# PIC32MZ1025W104132 device description
Architecture: MIPS; Family: PIC32MZW; Series: PIC32MZW
Registers are 32-bit, read-write, no defined reset value unless marked. A register's access mark holds for its fields unless they carry their own. Offsets are from the block's base; [hi:lo] are bit positions; {n}, {i} and the like mark numbered series; 'fields as' and 'values as' point back to an identical list.

## CVD
Instances: CVD 0x1f824000 in periph_pb2
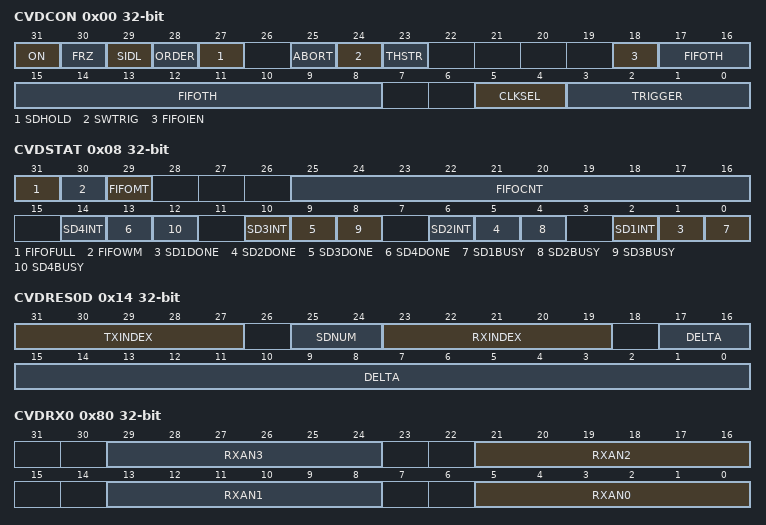
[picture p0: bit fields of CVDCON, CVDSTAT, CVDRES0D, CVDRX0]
0x00 CVDCON
  [31] ON, [30] FRZ, [29] SIDL, [28] ORDER, [27] SDHOLD, [25] ABORT, [24] SWTRIG, [23] THSTR, [18] FIFOIEN, [17:8] FIFOTH, [5:4] CLKSEL, [3:0] TRIGGER
0x04 CVDADC
  [23:0] ADCCON
0x08 CVDSTAT
  [31] FIFOFULL, [30] FIFOWM, [29] FIFOMT, [25:16] FIFOCNT, [4n-2] SD{n}INT (n=1..4), [4n-3] SD{n}DONE (n=1..4), [4n-4] SD{n}BUSY (n=1..4)
0x0C CVDRES0H
  [23:0] POS
0x10 CVDRES0L
  [23:0] NEG
0x14 CVDRES0D
  [31:27] TXINDEX, [25:24] SDNUM, [23:19] RXINDEX, [17:0] DELTA
0x80 CVDRX0
  [8n+5:8n] RXAN{n} (n=0..3)
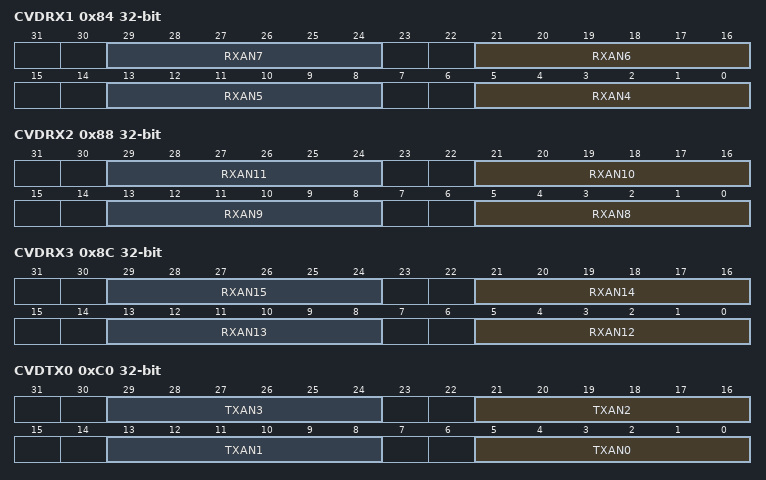
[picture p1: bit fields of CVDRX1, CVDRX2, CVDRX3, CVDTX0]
0x84 CVDRX1
  [8n-27:8n-32] RXAN{n} (n=4..7)
0x88 CVDRX2
  [8n-59:8n-64] RXAN{n} (n=8..11)
0x8C CVDRX3
  [8n-91:8n-96] RXAN{n} (n=12..15)
0xC0 CVDTX0
  [8n+5:8n] TXAN{n} (n=0..3)
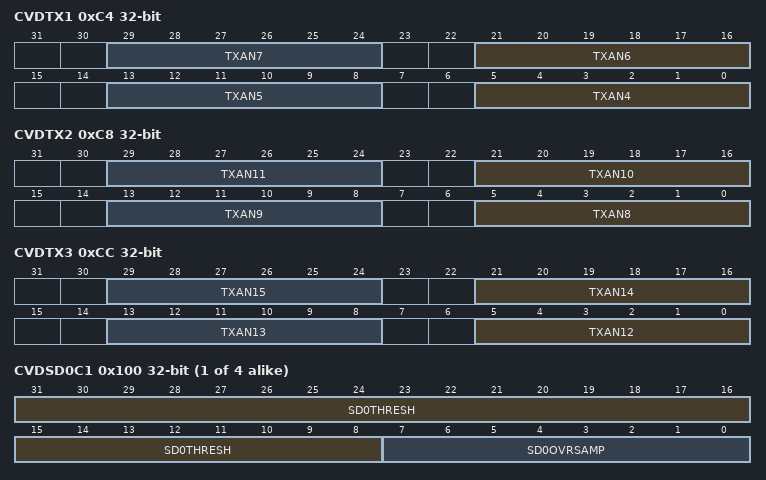
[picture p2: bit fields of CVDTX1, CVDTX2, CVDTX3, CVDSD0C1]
0xC4 CVDTX1
  [8n-27:8n-32] TXAN{n} (n=4..7)
0xC8 CVDTX2
  [8n-59:8n-64] TXAN{n} (n=8..11)
0xCC CVDTX3
  [8n-91:8n-96] TXAN{n} (n=12..15)
{0x100+0x10*i} CVDSD{i}C1 (i=0..3)
  [31:8] SD{i}THRESH, [7:0] SD{i}OVRSAMP
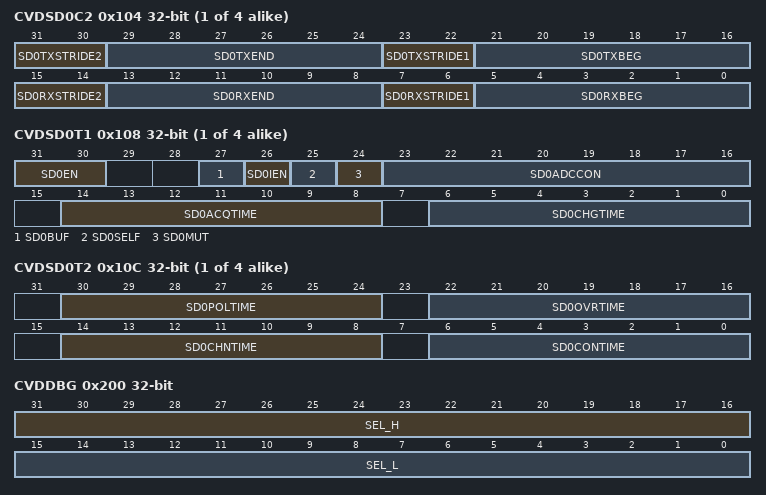
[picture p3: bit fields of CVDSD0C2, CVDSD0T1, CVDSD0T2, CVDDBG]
{0x104+0x10*i} CVDSD{i}C2 (i=0..3)
  [31:30] SD{i}TXSTRIDE2, [29:24] SD{i}TXEND, [23:22] SD{i}TXSTRIDE1, [21:16] SD{i}TXBEG, [15:14] SD{i}RXSTRIDE2, [13:8] SD{i}RXEND, [7:6] SD{i}RXSTRIDE1, [5:0] SD{i}RXBEG
{0x108+0x10*i} CVDSD{i}T1 (i=0..3)
  [31:30] SD{i}EN, [27] SD{i}BUF, [26] SD{i}IEN, [25] SD{i}SELF, [24] SD{i}MUT, [23:16] SD{i}ADCCON, [14:8] SD{i}ACQTIME, [6:0] SD{i}CHGTIME
{0x10C+0x10*i} CVDSD{i}T2 (i=0..3)
  [30:24] SD{i}POLTIME, [22:16] SD{i}OVRTIME, [14:8] SD{i}CHNTIME, [6:0] SD{i}CONTIME
0x200 CVDDBG
  [31:16] SEL_H, [15:0] SEL_L

## DMT
Instances: DMT 0x1f800a00 in periph_pb1a
0x00 DMTCON — Deadman Timer Control Register
  [15] ON — Deadman Timer Module Enable bit
    1=Deadman Timer module is enabled; 0=Deadman Timer module is disabled
0x10 DMTPRECLR — Deadman Timer Preclear Register
  [15:8] STEP1 — Preclear Enable bits
    64=Enables the Deadman Timer Preclear (Step 1)
0x20 DMTCLR — Deadman Timer Clear Register
  [7:0] STEP2 — Clear Timer bits
    8=Clears STEP1
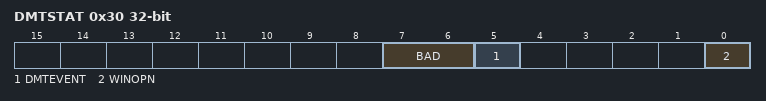
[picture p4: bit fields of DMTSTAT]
0x30 DMTSTAT ro — Deadman Timer Status Register
  [7:6] BAD
  [5] DMTEVENT — Deadman Timer Event bit
    1=Deadman timer event was detected (counter expired or bad STEP1 or STEP2 value was entered prior to counter increment); 0=Deadman timer even was not detected
  [0] WINOPN — Deadman Timer Clear Window bit
    1=Deadman timer clear window is open; 0=Deadman timer clear window is not open
0x40 DMTCNT ro — Deadman Timer Count Register
  [31:0] COUNTER
0x50 DMTHOLDREG ro
  [15:0] UPRCNT
0x60 DMTPSCNT ro — Post Status Configure DMT Count Status Register
  [31:0] PSCNT
0x70 DMTPSINTV ro — Post Status Configure DMT Interval Status Register
  [31:0] PSINTV
Value list DMTSTAT__BAD2: 2=Incorrect STEP2 value was detected; 0=Incorrect STEP2 value was not detected
Value list DMTSTAT__BAD1: 4=Incorrect STEP1 value or out of sequence write to STEP2 was detected; 0=Incorrect STEP1 value was not detected

## DSCTRL
Instances: DSCTRL 0x1f871000 in periph_pb4
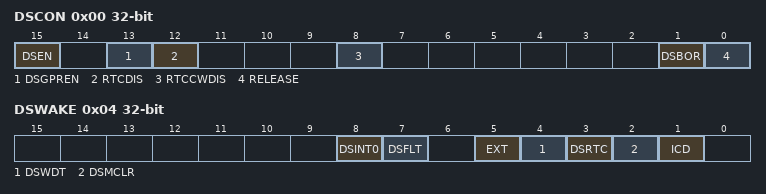
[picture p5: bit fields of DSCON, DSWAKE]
0x00 DSCON
  [15] DSEN, [13] DSGPREN, [12] RTCDIS, [8] RTCCWDIS, [1] DSBOR, [0] RELEASE
0x04 DSWAKE
  [8] DSINT0, [7] DSFLT, [5] EXT, [4] DSWDT, [3] DSRTC, [2] DSMCLR, [1] ICD
0x08 DSGPR0
  [31:0] DSGPR
{0xC+4i} DSGPR{i} (i=1..32)
  [31:0] DSGPR

## ICAP
Instances: ICAP 0x1f841000 in periph_pb3
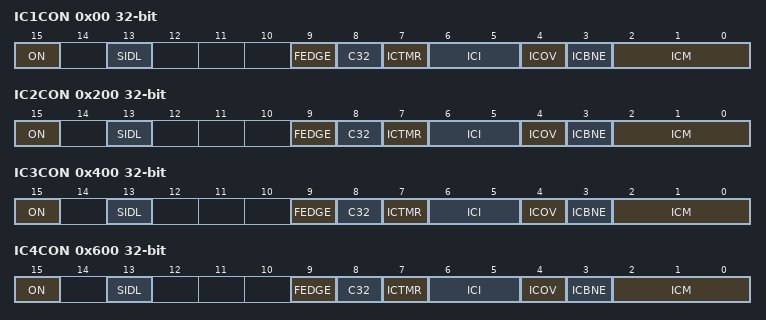
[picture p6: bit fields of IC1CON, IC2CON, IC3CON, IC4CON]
0x00 IC1CON — Input Capture 1 Control Register
  [15] ON — Input Capture Module Enable bit
    1=Module is enabled; 0=Disable and reset module, disable clocks, disable interrupt generation and allow SFR modifications
  [13] SIDL — Stop in Idle Control bit
    1=Halt in Idle mode; 0=Continue to operate in Idle mode
  [9] FEDGE — First Capture Edge Select bit
    1=Capture rising edge first; 0=Capture falling edge first
  [8] C32 — 32-bit Capture Select bit
    1=32-bit timer resource capture; 0=16-bit timer resource capture
  [7] ICTMR — Timer Select bit
    0=Timer3 is the counter source for capture; 1=Timer2 is the counter source for capture
  [6:5] ICI — Interrupt Control bits
    3=Interrupt on every fourth capture event; 2=Interrupt on every third capture event; 1=Interrupt on every second capture event; 0=Interrupt on every capture event
  [4] ICOV — Input Capture Overflow Status Flag bit (read-only)
    1=Input capture overflow has occurred; 0=No input capture overflow has occurred
  [3] ICBNE — Input Capture Buffer Not Empty Status bit (read-only)
    1=Input capture buffer is not empty; at least one more capture value can be read; 0=Input capture buffer is empty
  [2:0] ICM — Input Capture Mode Select bits
    7=Interrupt-Only mode (only supported while in Sleep mode or Idle mode); 6=Simple Capture Event mode every edge; 5=Prescaled Capture Event mode every sixteenth rising edge; 4=Prescaled Capture Event mode every fourth rising edge; 3=Simple Capture Event mode every rising edge; 2=Simple Capture Event mode every falling edge; 1=Edge Detect mode every edge (rising and falling); 0=Input Capture module is disabled
0x10 IC1BUF ro
0x200 IC2CON — Input Capture 1 Control Register
  fields as IC1CON
0x210 IC2BUF ro
0x400 IC3CON — Input Capture 1 Control Register
  fields as IC1CON
0x410 IC3BUF ro
0x600 IC4CON — Input Capture 1 Control Register
  fields as IC1CON
0x610 IC4BUF ro

## Notices in the file
Copyright (c) 2019 Microchip Technology Inc.
SPDX-License-Identifier: Apache-2.0
Licensed under the Apache License, Version 2.0 (the "License");
you may not use this file except in compliance with the License.
You may obtain a copy of the License at
http://www.apache.org/licenses/LICENSE-2.0
Unless required by applicable law or agreed to in writing, software
distributed under the License is distributed on an "AS IS" BASIS,
WITHOUT WARRANTIES OR CONDITIONS OF ANY KIND, either express or implied.
See the License for the specific language governing permissions and
limitations under the License.
